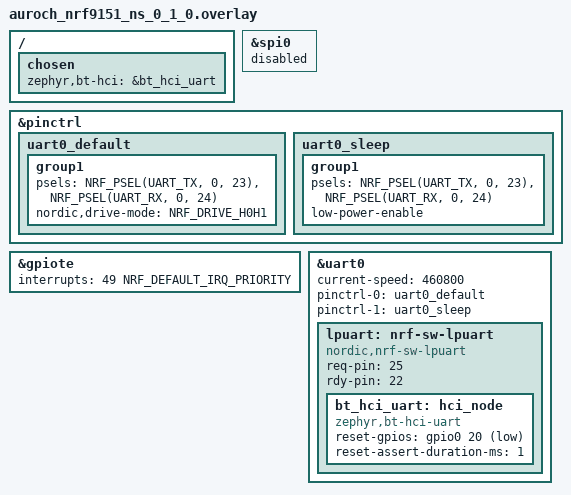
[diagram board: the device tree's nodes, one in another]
/* Use LPUART for HCI link instead of SPI due to nRF54L15 pin issues */

/delete-node/ &hci_spi;

&spi0 {
	status = "disabled";
};

/ {
	chosen {
		zephyr,bt-hci = &bt_hci_uart;
	};
};

&pinctrl {
	uart0_default: uart0_default {
		group1 {
			psels = <NRF_PSEL(UART_TX, 0, 23)>,
				<NRF_PSEL(UART_RX, 0, 24)>;
			nordic,drive-mode = <NRF_DRIVE_H0H1>;
		};
	};

	uart0_sleep: uart0_sleep {
		group1 {
			psels = <NRF_PSEL(UART_TX, 0, 23)>,
				<NRF_PSEL(UART_RX, 0, 24)>;
			low-power-enable;
		};
	};
};

&gpiote {
	/* GPIOTE and UART0 must have equal IRQ priorities */
	interrupts = <49 NRF_DEFAULT_IRQ_PRIORITY>;
};

&uart0 {
	current-speed = <460800>;
	status = "okay";
	pinctrl-0 = <&uart0_default>;
	pinctrl-1 = <&uart0_sleep>;
	pinctrl-names = "default", "sleep";

	lpuart: nrf-sw-lpuart {
		compatible = "nordic,nrf-sw-lpuart";
		status = "okay";
		req-pin = <25>;
		rdy-pin = <22>;

		bt_hci_uart: hci_node: bt_hci_uart {
			compatible = "zephyr,bt-hci-uart";
			status = "okay";
			reset-gpios = <&gpio0 20 (GPIO_ACTIVE_LOW)>;
			reset-assert-duration-ms = <1>;
		};
	};
};
